# STM32H743 register map
File version: 2.4
CPU: CM7 r0p1, little endian, MPU, FPU, 4 interrupt priority bits
Registers are 32-bit, read-write, reset 0x0 unless marked. A register's access mark holds for its fields unless they carry their own. Offsets are from the block's base; [hi:lo] are bit positions; {n}, {i} and the like mark numbered series; 'fields as' and 'values as' point back to an identical list.

## FMC — 灵活存储控制器（FMC）
Base 0x52004000
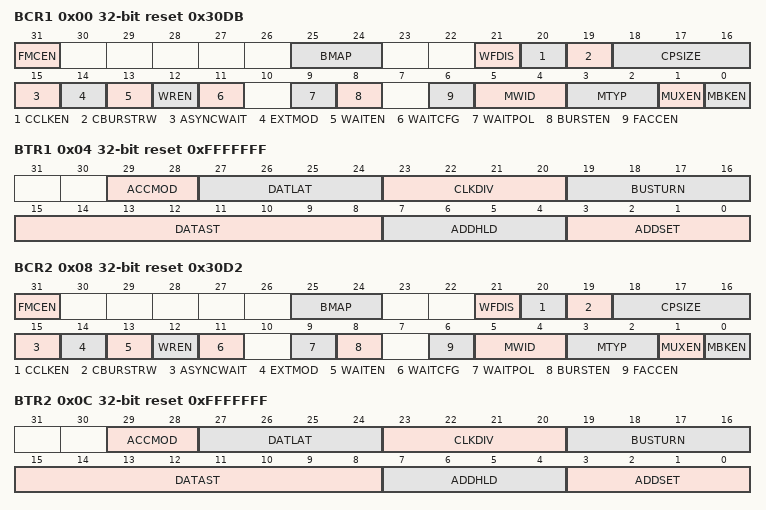
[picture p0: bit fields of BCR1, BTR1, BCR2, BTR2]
0x00 BCR1 reset 0x30DB — 该寄存器包含各存储 Bank 的控制信息，用于 SRAM、PSRAM 和 NOR Flash 存储器。
  [31] FMCEN — FMC 控制器使能。此位使能/禁止 FMC 控制器。注意：FMC_BCR2..4 寄存器中的 FMCEN 位无效，仅通过 FMC_BCR1 寄存器使能。
  [25:24] BMAP — FMC Bank 映射。这些位允许重映射 SDRAM Bank2 或交换 FMC NOR/PSRAM 与 SDRAM Bank。请参见表 10。注意：FMC_BCR2..4 寄存器中的 BMAP 位无效，仅通过 FMC_BCR1 寄存器使能。
  [21] WFDIS — 写 FIFO 禁止。此位禁止 FMC 控制器使用的写 FIFO。注意：FMC_BCR2..4 寄存器中的 WFDIS 位无效，仅通过 FMC_BCR1 寄存器使能。
  [20] CCLKEN — 连续时钟使能。此位使能输出到外部存储器件的 FMC_CLK 时钟。注意：FMC_BCR2..4 寄存器中的 CCLKEN 位无效，仅通过 FMC_BCR1 寄存器使能。Bank 1 必须配置为同步模式才能生成 FMC_CLK 连续时钟。若 CCLKEN 位置 1，FMC_CLK 时钟分频比由 FMC_BTR1 寄存器中的 CLKDIV 值指定，FMC_BWTR1 中的 CLKDIV 无效。若使用同步模式且 CCLKEN 位置 1，则连接到除 Bank 1 以外其他 Bank 的同步存储器由同一时钟驱动（其他 Bank 的 FMC_BTR2..4 和 FMC_BWTR2..4 寄存器中的 CLKDIV 值无效）。
  [19] CBURSTRW — 写突发使能。对于以突发模式工作的 PSRAM（CRAM），此位使能写操作期间的同步访问。同步读访问的使能位为 FMC_BCRx 寄存器中的 BURSTEN 位。
  [18:16] CPSIZE — CRAM 页大小。用于 Cellular RAM 1.5，该存储器不允许突发访问跨越页之间的地址边界。配置这些位后，当突发访问达到存储器页大小时，FMC 控制器会自动将其分割（页大小请参考存储器数据手册）。其他配置：保留。
  [15] ASYNCWAIT — 异步传输期间等待信号。此位使能/禁止 FMC 在异步协议期间也使用等待信号。
  [14] EXTMOD — 扩展模式使能。此位使能 FMC 在 FMC_BWTR 寄存器中编程异步访问的写时序，从而使读写操作使用不同的时序。注意：当扩展模式禁用时，FMC 可按 Mode1 或 Mode2 工作，规则如下：** 选择 SRAM/PSRAM 存储器类型（MTYP = 0x0 或 0x01）时，默认模式为 Mode 1；** 选择 NOR 存储器类型（MTYP = 0x10）时，默认模式为 Mode 2。
  [13] WAITEN — 等待使能位。此位使能/禁止通过 NWAIT 信号在同步模式下访问存储器时插入等待状态。
  [12] WREN — 写使能位。此位指示 FMC 在该 Bank 中的写操作是使能还是禁止：
  [11] WAITCFG — 等待时序配置。NWAIT 信号指示来自存储器的数据是否有效，或在同步模式下访问存储器时是否需要插入等待状态。此配置位决定 NWAIT 是在等待状态前一个时钟周期由存储器发出，还是在等待状态期间发出：
  [9] WAITPOL — 等待信号极性位。此位定义来自存储器的等待信号极性，同步或异步模式下均可使用：
  [8] BURSTEN — 突发使能位。此位使能/禁止读操作期间的同步访问。仅对以突发模式工作的同步存储器有效：
  [6] FACCEN — Flash 访问使能。此位使能 NOR Flash 存储器访问操作。
  [5:4] MWID — 存储器数据总线宽度。定义外部存储器件的宽度，对所有存储器类型均有效。
  [3:2] MTYP — 存储器类型。这些位定义对应存储 Bank 所连接的外部存储器类型：
  [1] MUXEN — 地址/数据复用使能位。此位置 1 时，地址与数据值在数据总线上复用，仅对 NOR 和 PSRAM 存储器有效：
  [0] MBKEN — 存储 Bank 使能位。此位用于使能存储 Bank。复位后 Bank1 使能，其余均禁用。访问被禁用的 Bank 会导致 AXI 总线产生 ERROR。
0x04 BTR1 reset 0xFFFFFFF — 该寄存器包含各存储 Bank 的控制信息，用于 SRAM、PSRAM 和 NOR Flash 存储器。若 FMC_BCRx 寄存器中的 EXTMOD 位置 1，则该寄存器被划分为写访问和读访问两部分，即提供 2 个寄存器：一个用于配置读访问（本寄存器），另一个用于配置写访问（FMC_BWTRx 寄存器）。
  [29:28] ACCMOD — 访问模式。这些位指定异步访问模式，如时序图所示。仅当 FMC_BCRx 寄存器中的 EXTMOD 位为 1 时才生效。
  [27:24] DATLAT — 同步存储器数据延迟。对于使能了读写突发模式的同步访问，这些位定义存储器时钟周期数。
  [23:20] CLKDIV — 时钟分频比（用于 FMC_CLK 信号）。这些位定义 FMC_CLK 时钟输出信号的周期，以 KCK_FMC 周期数表示：异步 NOR Flash、SRAM 或 PSRAM 访问中此值无效。注意：FMC_CLK 分频比公式请参见第 20.6.5 节：同步事务。
  [19:16] BUSTURN — 总线周转阶段持续时间。这些位由软件写入，用于在写转读或读转写事务结束时添加延迟。编程的总线周转延迟插入在异步读（复用模式或 Mode D）或写事务与对静态 Bank 的任何其他异步/同步读写之间。若执行读操作，Bank 可相同或不同；若为写操作，Bank 必须不同（复用模式或 Mode D 除外）。在某些情况下，无论 BUSTRUN 编程值为何，总线周转延迟按以下规则固定：除复用模式和 Mode D 外，对同一静态存储 Bank 的两次连续异步写传输之间不插入总线周转延迟。以下情况之间插入 1 个 FMC 时钟周期的总线周转延迟：对同一静态存储 Bank 的两次连续异步读传输（复用模式和 Mode D 除外）；异步读到对任何静态 Bank 或动态 Bank 的异步或同步写（复用模式和 Mode D 除外）。以下情况之间插入 2 个 FMC 时钟周期的总线周转延迟：对同一 Bank 的两次连续同步写操作（突发或单次模式）；同步写（突发或单次）访问与对静态存储 Bank 的异步写或读传输（读操作时 Bank 可相同或不同）；两次连续同步读操作（突发或单次模式）后接对另一静态存储 Bank 的任何同步/异步读或写。以下情况之间插入 3 个 FMC 时钟周期的总线周转延迟：对不同静态 Bank 的两次连续同步写操作（突发或单次模式）；同步写访问（突发或单次模式）与对相同或不同 Bank 的同步读。总线周转延迟用于匹配连续事务之间的最小时间（tEHEL，从 NEx 高电平到 NEx 低电平）以及存储器在读取后释放数据总线所需的最大时间（tEHQZ）：若 EXTMOD = 0，则 (BUSTRUN + 1) 个 KCK_FMC 周期 ≥ tEHELmin 且 (BUSTRUN + 2) 个 KCK_FMC 周期 ≥ tEHQZmax；若 EXTMOD = 1，则 (BUSTRUN + 2) 个 KCK_FMC 周期 ≥ max(tEHELmin, tEHQZmax)。...
  [15:8] DATAST — 数据阶段持续时间。这些位由软件写入，用于定义数据阶段的持续时间（参见图 81 至图 93），用于异步访问：各存储器类型和访问模式的数据阶段持续时间请参见对应图示（图 81 至图 93）。示例：Mode1，写访问，DATAST=1：数据阶段持续时间 = DATAST+1 = 2 个 KCK_FMC 时钟周期。注意：同步访问中此值无效。
  [7:4] ADDHLD — 地址保持阶段持续时间。这些位由软件写入，用于定义地址保持阶段的持续时间（参见图 81 至图 93），用于 Mode D 或复用访问：各访问模式的地址保持阶段持续时间请参见对应图示（图 81 至图 93）。注意：同步访问中不使用此值，地址保持阶段始终为 1 个存储器时钟周期。
  [3:0] ADDSET — 地址建立阶段持续时间。这些位由软件写入，用于定义地址建立阶段的持续时间（参见图 81 至图 93），用于 SRAM、ROM 和异步 NOR Flash：各访问模式的地址建立阶段持续时间请参见对应图示（参见图 81 至图 93）。注意：同步访问中此值无效。在复用模式或 Mode D 下，ADDSET 的最小值为 1。
0x08 BCR2 reset 0x30D2 — 该寄存器包含各存储 Bank 的控制信息，用于 SRAM、PSRAM 和 NOR Flash 存储器。
  fields as BCR1
0x0C BTR2 reset 0xFFFFFFF — 该寄存器包含各存储 Bank 的控制信息，用于 SRAM、PSRAM 和 NOR Flash 存储器。若 FMC_BCRx 寄存器中的 EXTMOD 位置 1，则该寄存器被划分为写访问和读访问两部分，即提供 2 个寄存器：一个用于配置读访问（本寄存器），另一个用于配置写访问（FMC_BWTRx 寄存器）。
  fields as BTR1
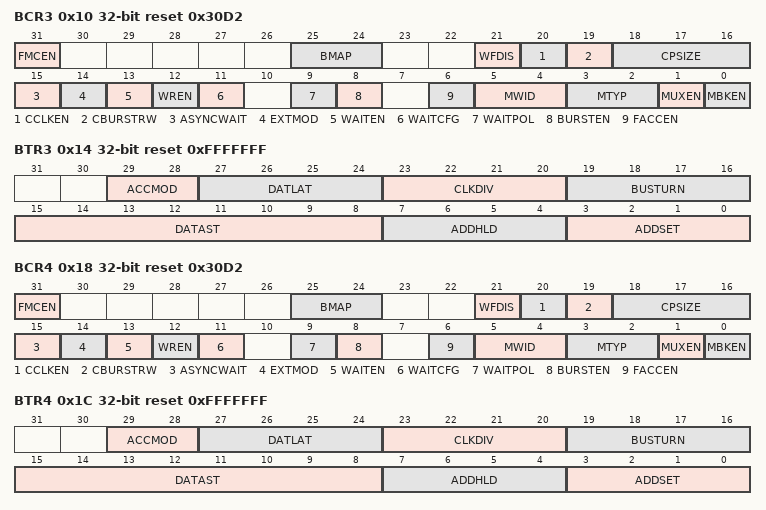
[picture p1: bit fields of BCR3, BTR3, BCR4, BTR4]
0x10 BCR3 reset 0x30D2 — 该寄存器包含各存储 Bank 的控制信息，用于 SRAM、PSRAM 和 NOR Flash 存储器。
  fields as BCR1
0x14 BTR3 reset 0xFFFFFFF — 该寄存器包含各存储 Bank 的控制信息，用于 SRAM、PSRAM 和 NOR Flash 存储器。若 FMC_BCRx 寄存器中的 EXTMOD 位置 1，则该寄存器被划分为写访问和读访问两部分，即提供 2 个寄存器：一个用于配置读访问（本寄存器），另一个用于配置写访问（FMC_BWTRx 寄存器）。
  fields as BTR1
0x18 BCR4 reset 0x30D2 — 该寄存器包含各存储 Bank 的控制信息，用于 SRAM、PSRAM 和 NOR Flash 存储器。
  fields as BCR1
0x1C BTR4 reset 0xFFFFFFF — 该寄存器包含各存储 Bank 的控制信息，用于 SRAM、PSRAM 和 NOR Flash 存储器。若 FMC_BCRx 寄存器中的 EXTMOD 位置 1，则该寄存器被划分为写访问和读访问两部分，即提供 2 个寄存器：一个用于配置读访问（本寄存器），另一个用于配置写访问（FMC_BWTRx 寄存器）。
  fields as BTR1
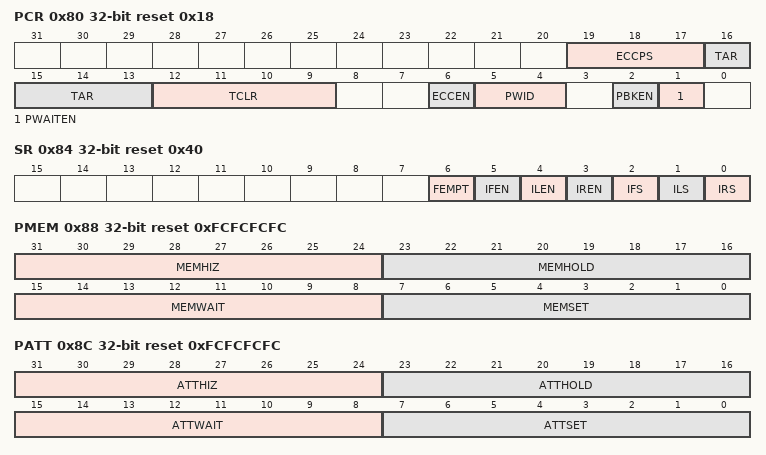
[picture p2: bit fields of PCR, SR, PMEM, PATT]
0x80 PCR reset 0x18 — NAND Flash 控制寄存器
  [19:17] ECCPS — ECC 页大小。这些位定义扩展 ECC 的页大小：
  [16:13] TAR — ALE 到 RE 延迟。这些位以 KCK_FMC 时钟周期数设置从 ALE 低电平到 RE 低电平的时间。时间为：t_ar = (TAR + SET + 2) × TKCK_FMC，其中 TKCK_FMC 为 FMC 时钟周期。注意：SET 为 MEMSET 或 ATTSET，取决于所寻址的空间。
  [12:9] TCLR — CLE 到 RE 延迟。这些位以 KCK_FMC 时钟周期数设置从 CLE 低电平到 RE 低电平的时间。时间由以下公式给出：t_clr = (TCLR + SET + 2) × TKCK_FMC，其中 TKCK_FMC 为 KCK_FMC 时钟周期。注意：SET 为 MEMSET 或 ATTSET，取决于所寻址的空间。
  [6] ECCEN — ECC 计算逻辑使能位
  [5:4] PWID — 数据总线宽度。这些位定义外部存储器件的宽度。
  [2] PBKEN — NAND Flash 存储 Bank 使能位。此位使能存储 Bank。访问被禁用的存储 Bank 会导致 AXI 总线产生 ERROR。
  [1] PWAITEN — 等待特性使能位。此位使能 NAND Flash 存储 Bank 的等待特性：
0x84 SR access per field reset 0x40 — 该寄存器包含 FIFO 状态和中断信息。FMC 具有一个 FIFO，用于在写入存储器时缓冲最多 16 个字的数据。这用于快速写入 FIFO 并释放 AXI 总线用于访问 FMC 以外的外设，同时 FMC 将其 FIFO 中的数据排空到存储器中。其中一个寄存器位指示 FIFO 的状态，用于 ECC 相关目的。ECC 在数据写入存储器时计算。为了读取正确的 ECC，软件必须等待 FIFO 为空。
  [6] FEMPT ro — FIFO 为空。只读位，提供 FIFO 的状态。
  [5] IFEN rw — 中断下降沿检测使能位
  [4] ILEN rw — 中断高电平检测使能位
  [3] IREN rw — 中断上升沿检测使能位
  [2] IFS rw — 中断下降沿状态。该标志由硬件置位，由软件复位。注意：如果软件向此位写入 1，它将置位。
  [1] ILS rw — 中断高电平状态。该标志由硬件置位，由软件复位。
  [0] IRS rw — 中断上升沿状态。该标志由硬件置位，由软件复位。注意：如果软件向此位写入 1，它将置位。
0x88 PMEM reset 0xFCFCFCFC — FMC_PMEM 读写寄存器包含 NAND Flash 存储 Bank 的时序信息。该信息用于访问 NAND Flash 的公共存储空间，以进行命令、地址写访问和数据读写访问。
  [31:24] MEMHIZ — 公共存储器数据总线高阻态时间。这些位定义在 NAND Flash 对公共存储空间写访问启动后，数据总线保持高阻态的 KCK_FMC 时钟周期数。仅对写事务有效：
  [23:16] MEMHOLD — 公共存储器保持时间。这些位定义在命令（NWE、NOE）无效后地址保持（写访问时还包括数据保持）的 KCK_FMC 时钟周期数（写访问）和 KCK_FMC+1 时钟周期数（读访问），用于对公共存储空间的 NAND Flash 读写访问：
  [15:8] MEMWAIT — 公共存储器等待时间。这些位定义命令（NWE、NOE）有效的最小 KCK_FMC 时钟周期数（+1），用于对公共存储空间的 NAND Flash 读写访问。若等待信号（NWAIT）在编程的 KCK_FMC 值结束时为有效（低电平），则命令有效的持续时间将被延长：
  [7:0] MEMSET — 公共存储器建立时间。这些位定义在命令（NWE、NOE）有效之前、用于建立地址的 KCK_FMC 时钟周期数（+1），用于对公共存储空间的 NAND Flash 读写访问：
0x8C PATT reset 0xFCFCFCFC — FMC_PATT 读写寄存器包含 NAND Flash 存储 Bank 的时序信息。用于对 NAND Flash 属性存储空间的 8 位访问，当最后一次地址写访问的时序必须与此前访问的时序不同时使用（就绪/忙管理请参见第 20.8.5 节：NAND Flash 预等待特性）。
  [31:24] ATTHIZ — 属性存储器数据总线高阻态时间。这些位定义在 NAND Flash 对插槽上的属性存储空间写访问启动后，数据总线保持高阻态的 KCK_FMC 时钟周期数。仅对写事务有效：
  [23:16] ATTHOLD — 属性存储器保持时间。这些位定义在命令（NWE、NOE）无效后地址保持（写访问时还包括数据保持）的 KCK_FMC 时钟周期数，用于对属性存储空间的 NAND Flash 读写访问：
  [15:8] ATTWAIT — 属性存储器等待时间。这些位定义命令（NWE、NOE）有效的最小 KCK_FMC 时钟周期数（+1），用于对属性存储空间的 NAND Flash 读写访问。若等待信号（NWAIT）在编程的 KCK_FMC 值结束时为有效（低电平），则命令有效的持续时间将被延长：
  [7:0] ATTSET — 属性存储器建立时间。这些位定义在命令（NWE、NOE）有效之前、用于建立地址的 KCK_FMC 时钟周期数（+1），用于对属性存储空间的 NAND Flash 读写访问：
0x94 ECCR ro — 该寄存器包含由 FMC NAND 控制器的 ECC 计算模块计算出的当前纠错码值。当 CPU 以正确的地址读/写 NAND Flash 存储器页的数据时（参见第 20.8.6 节：NAND Flash 存储器中纠错码（ECC）的计算），从/向 NAND Flash 存储器读/写的数据由 ECC 计算模块自动处理。读取了 X 字节后（根据 FMC_PCR 寄存器中的 ECCPS 字段），CPU 必须从 FMC_ECC 寄存器中读取计算出的 ECC 值，然后校验这些计算出的校验数据是否与记录在备用区的校验值相同，以确定页是否有效，并在无效时进行纠正。FMC_ECCR 寄存器在读出后应通过将 ECCEN 位清零来清除。要计算新的数据块，必须将 ECCEN 位置 1。
  [31:0] ECC — ECC 结果。该字段包含由 ECC 计算逻辑计算出的值。表 167 描述了这些位字段的内容。
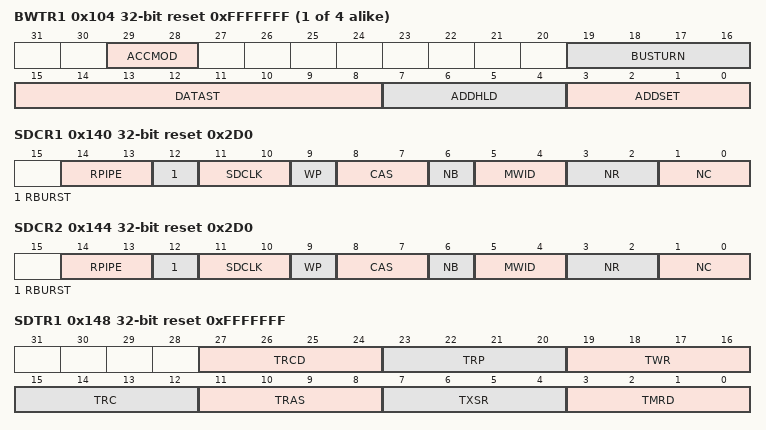
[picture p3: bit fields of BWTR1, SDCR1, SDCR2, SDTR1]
{0xFC+8i} BWTR{i} reset 0xFFFFFFF (i=1..4) — 该寄存器包含各存储 Bank 的控制信息，用于 SRAM、PSRAM 和 NOR Flash 存储器。当 FMC_BCRx 寄存器中的 EXTMOD 位置 1 时，本寄存器对写访问有效。
  [29:28] ACCMOD — 访问模式。这些位指定异步访问模式，如后续时序图所示。仅当 FMC_BCRx 寄存器中的 EXTMOD 位为 1 时才生效。
  [19:16] BUSTURN — 总线周转阶段持续时间。这些位由软件写入，用于在写事务结束时添加延迟，以匹配连续事务之间的最小时间（tEHEL，从 ENx 高电平到 ENx 低电平）：(BUSTRUN + 1) 个 KCK_FMC 周期 ≥ tEHELmin。编程的总线周转延迟插入在异步写传输与对静态 Bank 的任何其他异步/同步读或写传输之间。若执行读操作，Bank 可相同或不同；若为写操作，Bank 必须不同（复用模式或 Mode D 除外）。在某些情况下，无论 BUSTRUN 编程值为何，总线周转延迟按以下规则固定：除复用模式和 Mode D 外，对同一静态存储 Bank 的两次连续异步写传输之间不插入总线周转延迟。以下情况之间插入 2 个 FMC 时钟周期的总线周转延迟：对同一 Bank 的两次连续同步写操作（突发或单次模式）；同步写传输（突发或单次模式）与对静态存储 Bank 的异步写或读传输。以下情况之间插入 3 个 FMC 时钟周期的总线周转延迟：对不同静态 Bank 的两次连续同步写操作（突发或单次模式）；同步写传输（突发或单次模式）与对相同或不同 Bank 的同步读。...
  [15:8] DATAST — 数据阶段持续时间。这些位由软件写入，用于定义数据阶段的持续时间（参见图 81 至图 93），用于异步 SRAM、PSRAM 和 NOR Flash 存储器访问：
  [7:4] ADDHLD — 地址保持阶段持续时间。这些位由软件写入，用于定义地址保持阶段的持续时间（参见图 81 至图 93），用于异步复用访问：... 注意：同步 NOR Flash 访问中不使用此值，地址保持阶段始终为 1 个 Flash 时钟周期。
  [3:0] ADDSET — 地址建立阶段持续时间。这些位由软件写入，用于定义地址建立阶段的持续时间，以 KCK_FMC 周期数表示（参见图 81 至图 93），用于异步访问：... 注意：同步访问中不使用此值，地址建立阶段始终为 1 个 Flash 时钟周期。在复用模式下，ADDSET 的最小值为 1。
0x140 SDCR1 reset 0x2D0 — 该寄存器包含各 SDRAM 存储 Bank 的控制参数
  [14:13] RPIPE — 读流水线。这些位定义 CAS 延迟后读取数据的延迟，以 KCK_FMC 时钟周期数表示。注意：FMC_SDCR2 寄存器中的对应位为只读。
  [12] RBURST — 突发读。此位使能突发读模式。SDRAM 控制器在 CAS 延迟期间预取下一个读命令并将数据存储在读 FIFO 中。注意：FMC_SDCR2 寄存器中的对应位为只读。
  [11:10] SDCLK — SDRAM 时钟配置。这些位为两个 SDRAM Bank 定义 SDRAM 时钟周期，并允许在更改频率之前禁用时钟。在这种情况下，SDRAM 必须重新初始化。注意：FMC_SDCR2 寄存器中的对应位为只读。
  [9] WP — 写保护。此位使能对 SDRAM Bank 的写模式访问。
  [8:7] CAS — CAS 延迟。这些位以存储器时钟周期数设置 SDRAM CAS 延迟。
  [6] NB — 内部 Bank 数量。此位设置内部 Bank 的数量。
  [5:4] MWID — 存储器数据总线宽度。这些位定义存储器件的宽度。
  [3:2] NR — 行地址位数。这些位定义行地址的位数。
  [1:0] NC — 列地址位数。这些位定义列地址的位数。
0x144 SDCR2 reset 0x2D0 — 该寄存器包含各 SDRAM 存储 Bank 的控制参数
  fields as SDCR1
0x148 SDTR1 reset 0xFFFFFFF — 该寄存器包含各 SDRAM Bank 的时序参数
  [27:24] TRCD — 行到列延迟。这些位定义激活命令与读/写命令之间的延迟，以存储器时钟周期数表示。....
  [23:20] TRP — 行预充电延迟。这些位定义预充电命令与另一命令之间的延迟，以存储器时钟周期数表示。TRP 时序仅在 FMC_SDTR1 寄存器中配置。若使用两片 SDRAM 器件，TRP 必须编程为较慢器件的时序。.... 注意：FMC_SDTR2 寄存器中的对应位无效。
  [19:16] TWR — 恢复延迟。这些位定义写命令与预充电命令之间的延迟，以存储器时钟周期数表示。.... 注意：TWR 必须编程为与 SDRAM 数据手册中定义的写恢复时间（tWR）匹配，并保证：TWR ≥ TRAS - TRCD 且 TWR ≥ TRC - TRCD - TRP。示例：TRAS = 4 个周期，TRCD = 2 个周期，则 TWR >= 2 个周期，TWR 必须编程为 0x1。若使用两片 SDRAM 器件，FMC_SDTR1 和 FMC_SDTR2 必须编程为与较慢 SDRAM 器件对应的相同 TWR 时序。
  [15:12] TRC — 行周期延迟。这些位定义刷新命令与激活命令之间的延迟，以及两次连续刷新命令之间的延迟，以存储器时钟周期数表示。TRC 时序仅在 FMC_SDTR1 寄存器中配置。若使用两片 SDRAM 器件，TRC 必须编程为较慢器件的时序。.... 注意：TRC 必须与 SDRAM 器件数据手册中定义的 TRC 和 TRFC（自动刷新周期）时序匹配。注意：FMC_SDTR2 寄存器中的对应位无效。
  [11:8] TRAS — 自刷新时间。这些位定义最小自刷新周期，以存储器时钟周期数表示。....
  [7:4] TXSR — 退出自刷新延迟。这些位定义从释放自刷新命令到发出激活命令之间的延迟，以存储器时钟周期数表示。.... 注意：若使用两片 SDRAM 器件，FMC_SDTR1 和 FMC_SDTR2 必须编程为与较慢 SDRAM 器件对应的相同 TXSR 时序。
  [3:0] TMRD — 加载模式寄存器到激活。这些位定义加载模式寄存器命令与激活或刷新命令之间的延迟，以存储器时钟周期数表示。....
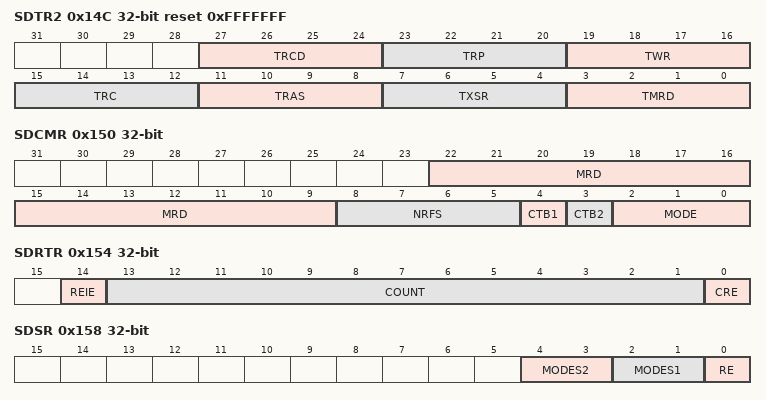
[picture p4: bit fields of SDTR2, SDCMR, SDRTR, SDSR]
0x14C SDTR2 reset 0xFFFFFFF — 该寄存器包含各 SDRAM Bank 的时序参数
  fields as SDTR1
0x150 SDCMR — 该寄存器包含访问 SDRAM 器件时发出的命令。此寄存器用于初始化 SDRAM 器件，以及激活自刷新和掉电模式。一旦写入 MODE 字段，命令将根据 CTB1 和 CTB2 命令位仅发送到一个或两个 SDRAM Bank。此寄存器对两个 SDRAM Bank 通用。
  [22:9] MRD — 模式寄存器定义。此 14 位字段定义 SDRAM 模式寄存器的内容。模式寄存器通过加载模式寄存器命令进行编程。MRD[13:0] 位也用于编程移动 SDRAM 的扩展模式寄存器。
  [8:5] NRFS — 自动刷新次数。这些位定义当 MODE = 011 时发出的连续自动刷新命令的次数。....
  [4] CTB1 — 命令目标 Bank 1。此位指示命令是否发送到 SDRAM Bank 1。
  [3] CTB2 — 命令目标 Bank 2。此位指示命令是否发送到 SDRAM Bank 2。
  [2:0] MODE — 命令模式。这些位定义发送到 SDRAM 器件的命令。注意：发出命令时，必须至少设置一个命令目标 Bank 位（CTB1 或 CTB2），否则命令将被忽略。注意：若使用两个 SDRAM Bank，自动刷新和 PALL 命令必须同时发送到两个器件，且 CTB1 和 CTB2 位均置位，否则命令将被忽略。注意：若仅使用一个 SDRAM Bank 且发出了命令并设置了其关联的 CTB 位，则未用 Bank 的另一个 CTB 位必须保持为 0。
0x154 SDRTR access per field — 该寄存器通过配置刷新定时器计数值，以 SDCLK 时钟周期数设置刷新周期之间的刷新速率。示例中 64 ms 为 SDRAM 刷新周期。如果内部刷新请求在读请求已被接受时发生，刷新速率必须增加 20 个 SDRAM 时钟周期（如上例）以获得安全余量，对应 COUNT 值为 0000111000000（448）。此 13 位字段被加载到一个使用 SDRAM 时钟递减的定时器中。当计数达到零时，该定时器产生一个刷新脉冲。COUNT 值必须至少设置为 41 个 SDRAM 时钟周期。一旦编程了 FMC_SDRTR 寄存器，定时器就开始计数。如果寄存器中编程的值为 0，则不执行刷新。初始化过程之后不得重新编程此寄存器，以避免修改刷新速率。每次产生刷新脉冲时，此 13 位 COUNT 字段被重新加载到计数器中。如果正在进行存储器访问，自动刷新请求将被延迟。但是，如果存储器访问和自动刷新请求同时产生，则自动刷新优先。如果存储器访问在刷新操作期间发生，则请求被缓冲，待刷新完成后处理。此寄存器对 SDRAM Bank 1 和 Bank 2 通用。
  [14] REIE rw — 刷新错误（RE）中断使能
  [13:1] COUNT rw — 刷新定时器计数值。此 13 位字段定义 SDRAM 器件的刷新速率，以存储器时钟周期数表示。必须至少设置为 41 个 SDRAM 时钟周期（0x29）。刷新速率 = (COUNT + 1) × SDRAM 时钟频率，COUNT = (SDRAM 刷新周期 / 行数) - 20
  [0] CRE wo — 清除刷新错误标志。此位用于清除状态寄存器中的刷新错误标志（RE）。
0x158 SDSR ro — SDRAM 状态寄存器
  [4:3] MODES2 — Bank 2 状态模式。这些位定义 SDRAM Bank 2 的状态模式。
  [2:1] MODES1 — Bank 1 状态模式。这些位定义 SDRAM Bank 1 的状态模式。
  [0] RE — 刷新错误标志。若 REIE = 1 且 RE = 1，则产生中断。
